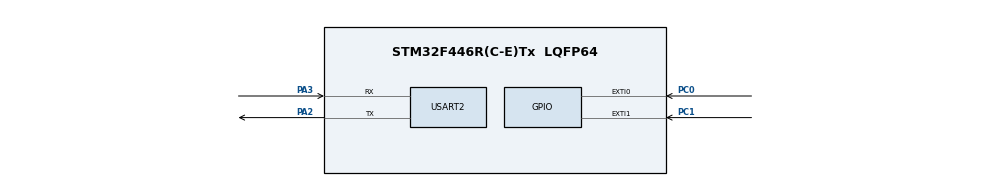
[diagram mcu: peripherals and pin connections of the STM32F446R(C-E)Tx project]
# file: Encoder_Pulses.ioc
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Mcu.Family=STM32F4
Mcu.Name=STM32F446R(C-E)Tx
Mcu.Package=LQFP64
NVIC.EXTI0_IRQn=true\:0\:0\:false\:false\:true\:true\:true
NVIC.EXTI1_IRQn=true\:0\:0\:false\:false\:true\:true\:true
NVIC.PriorityGroup=NVIC_PRIORITYGROUP_4
PA13.Mode=Serial_Wire
PA13.Signal=SYS_JTMS-SWDIO
PA14.Mode=Serial_Wire
PA14.Signal=SYS_JTCK-SWCLK
PA2.Mode=Asynchronous
PA2.Signal=USART2_TX
PA3.Mode=Asynchronous
PA3.Signal=USART2_RX
PC0.Signal=GPXTI0
PC1.Signal=GPXTI1
PH0-OSC_IN.Mode=HSE-External-Oscillator
PH0-OSC_IN.Signal=RCC_OSC_IN
PH1-OSC_OUT.Mode=HSE-External-Oscillator
PH1-OSC_OUT.Signal=RCC_OSC_OUT
ProjectManager.HeapSize=0x200
ProjectManager.StackSize=0x400
ProjectManager.TargetToolchain=STM32CubeIDE
RCC.CortexFreq_Value=16000000
RCC.USBFreq_Value=96000000
RCC.VCOOutputFreq_Value=192000000
USART2.VirtualMode=VM_ASYNC
board=custom

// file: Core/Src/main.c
/* USER CODE BEGIN Header */
/**
  ******************************************************************************
  * @file           : main.c
  * @brief          : Main program body
  ******************************************************************************
  * @attention
  *
  * <h2><center>&copy; Copyright (c) 2021 STMicroelectronics.
  * All rights reserved.</center></h2>
  *
  * This software component is licensed by ST under BSD 3-Clause license,
  * the "License"; You may not use this file except in compliance with the
  * License. You may obtain a copy of the License at:
  *                        opensource.org/licenses/BSD-3-Clause
  *
  ******************************************************************************
  */
/* USER CODE END Header */
#include "main.h"
#include "string.h"
/* USER CODE BEGIN Includes */
#include<stdbool.h>
uint8_t TurnsDetected,PrevTurnsDetected;
int count=0,previouscount,rotationDirection;
char buffer[100];
/* USER CODE END Includes */

UART_HandleTypeDef huart2;

void SystemClock_Config(void);
static void MX_GPIO_Init(void);
static void MX_USART2_UART_Init(void);
int Encoder_Pulses();

int main(void)
{

  /* MCU Configuration--------------------------------------------------------*/

  /* Reset of all peripherals, Initializes the Flash interface and the Systick. */
  HAL_Init();

  /* Configure the system clock */
  SystemClock_Config();

  /* Initialize all configured peripherals */
  MX_GPIO_Init();
  MX_USART2_UART_Init();

  /* Infinite loop */
  while (1)
  {
	  Encoder_Pulses();
    /* USER CODE BEGIN 3 */

    /* USER CODE BEGIN 3 */
  }
  /* USER CODE END 3 */
}

int Encoder_Pulses()
{
	    if(TurnsDetected)
		    {
		  	  TurnsDetected=0;
		  	  if(rotationDirection)
		  		  count+=1;
		  	  else if(!rotationDirection)
		  		  count-=1;
		    }
		      /* USER CODE BEGIN 3 */
	        previouscount=count;
	        HAL_UART_Transmit(&huart2, (uint8_t*)buffer, sprintf(buffer,"\n Encoder_Pulses_Value: %d",count),1000);
	        return(count);
}

void SystemClock_Config(void)
{
  RCC_OscInitTypeDef RCC_OscInitStruct = {0};
  RCC_ClkInitTypeDef RCC_ClkInitStruct = {0};

  /** Configure the main internal regulator output voltage
  */
  __HAL_RCC_PWR_CLK_ENABLE();
  __HAL_PWR_VOLTAGESCALING_CONFIG(PWR_REGULATOR_VOLTAGE_SCALE3);
  /** Initializes the RCC Oscillators according to the specified parameters
  * in the RCC_OscInitTypeDef structure.
  */
  RCC_OscInitStruct.OscillatorType = RCC_OSCILLATORTYPE_HSI;
  RCC_OscInitStruct.HSIState = RCC_HSI_ON;
  RCC_OscInitStruct.HSICalibrationValue = RCC_HSICALIBRATION_DEFAULT;
  RCC_OscInitStruct.PLL.PLLState = RCC_PLL_NONE;
  if (HAL_RCC_OscConfig(&RCC_OscInitStruct) != HAL_OK)
  {
    Error_Handler();
  }
  /** Initializes the CPU, AHB and APB buses clocks
  */
  RCC_ClkInitStruct.ClockType = RCC_CLOCKTYPE_HCLK|RCC_CLOCKTYPE_SYSCLK
                              |RCC_CLOCKTYPE_PCLK1|RCC_CLOCKTYPE_PCLK2;
  RCC_ClkInitStruct.SYSCLKSource = RCC_SYSCLKSOURCE_HSI;
  RCC_ClkInitStruct.AHBCLKDivider = RCC_SYSCLK_DIV1;
  RCC_ClkInitStruct.APB1CLKDivider = RCC_HCLK_DIV1;
  RCC_ClkInitStruct.APB2CLKDivider = RCC_HCLK_DIV1;

  if (HAL_RCC_ClockConfig(&RCC_ClkInitStruct, FLASH_LATENCY_0) != HAL_OK)
  {
    Error_Handler();
  }
}

static void MX_USART2_UART_Init(void)
{

  huart2.Instance = USART2;
  huart2.Init.BaudRate = 115200;
  huart2.Init.WordLength = UART_WORDLENGTH_8B;
  huart2.Init.StopBits = UART_STOPBITS_1;
  huart2.Init.Parity = UART_PARITY_NONE;
  huart2.Init.Mode = UART_MODE_TX_RX;
  huart2.Init.HwFlowCtl = UART_HWCONTROL_NONE;
  huart2.Init.OverSampling = UART_OVERSAMPLING_16;
  if (HAL_UART_Init(&huart2) != HAL_OK)
  {
    Error_Handler();
  }

}

static void MX_GPIO_Init(void)
{
  GPIO_InitTypeDef GPIO_InitStruct = {0};

  /* GPIO Ports Clock Enable */
  __HAL_RCC_GPIOH_CLK_ENABLE();
  __HAL_RCC_GPIOC_CLK_ENABLE();
  __HAL_RCC_GPIOA_CLK_ENABLE();

  /*Configure GPIO pins : PC0 PC1 */
  GPIO_InitStruct.Pin = GPIO_PIN_0|GPIO_PIN_1;
  GPIO_InitStruct.Mode = GPIO_MODE_IT_RISING;
  GPIO_InitStruct.Pull = GPIO_NOPULL;
  HAL_GPIO_Init(GPIOC, &GPIO_InitStruct);

  /* EXTI interrupt init*/
  HAL_NVIC_SetPriority(EXTI0_IRQn, 0, 0);
  HAL_NVIC_EnableIRQ(EXTI0_IRQn);

  HAL_NVIC_SetPriority(EXTI1_IRQn, 0, 0);
  HAL_NVIC_EnableIRQ(EXTI1_IRQn);

}

void Error_Handler(void)
{
  __disable_irq();
  while (1)
  {
  }
}

/************************ (C) COPYRIGHT STMicroelectronics *****END OF FILE****/
